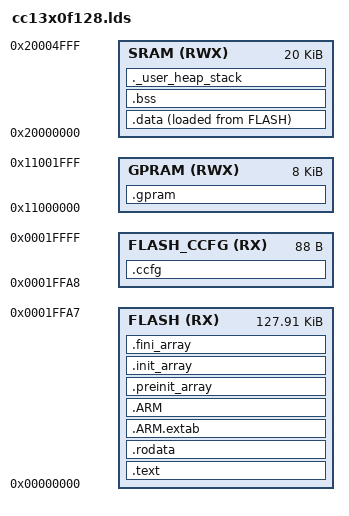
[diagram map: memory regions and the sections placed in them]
/*
 @file       cc13x0f128.lds
 @brief      CC13x0F128 linker configuration file for GNU compiler.

 @Revised     $Date: 2015-11-20 13:19:16 +0100 (fr, 20 nov 2015) $
 @Revision    $Revision: 16378 $

  Copyright (C) 2015 Texas Instruments Incorporated - http:www.ti.com/


  Redistribution and use in source and binary forms, with or without
  modification, are permitted provided that the following conditions
  are met:

    Redistributions of source code must retain the above copyright
    notice, this list of conditions and the following disclaimer.

    Redistributions in binary form must reproduce the above copyright
    notice, this list of conditions and the following disclaimer in the
    documentation and/or other materials provided with the distribution.

    Neither the name of Texas Instruments Incorporated nor the names of
    its contributors may be used to endorse or promote products derived
    from this software without specific prior written permission.

  THIS SOFTWARE IS PROVIDED BY THE COPYRIGHT HOLDERS AND CONTRIBUTORS
  "AS IS" AND ANY EXPRESS OR IMPLIED WARRANTIES, INCLUDING, BUT NOT
  LIMITED TO, THE IMPLIED WARRANTIES OF MERCHANTABILITY AND FITNESS FOR
  A PARTICULAR PURPOSE ARE DISCLAIMED. IN NO EVENT SHALL THE COPYRIGHT
  OWNER OR CONTRIBUTORS BE LIABLE FOR ANY DIRECT, INDIRECT, INCIDENTAL,
  SPECIAL, EXEMPLARY, OR CONSEQUENTIAL DAMAGES (INCLUDING, BUT NOT
  LIMITED TO, PROCUREMENT OF SUBSTITUTE GOODS OR SERVICES; LOSS OF USE,
  DATA, OR PROFITS; OR BUSINESS INTERRUPTION) HOWEVER CAUSED AND ON ANY
  THEORY OF LIABILITY, WHETHER IN CONTRACT, STRICT LIABILITY, OR TORT
  (INCLUDING NEGLIGENCE OR OTHERWISE) ARISING IN ANY WAY OUT OF THE USE
  OF THIS SOFTWARE, EVEN IF ADVISED OF THE POSSIBILITY OF SUCH DAMAGE.
*/

/* Entry Point */
ENTRY( ResetISR )

/* System memory map */
MEMORY
{
    /* Application stored in and executes from internal flash */
    /* Flash Size 128 KB */
    FLASH (RX) : ORIGIN = 0x0, LENGTH = 0x0001FFA8
    /* Customer Configuration Area (CCFG) */
    FLASH_CCFG (RX) : ORIGIN = 0x1FFA8, LENGTH = 88
    /* Application uses internal RAM for data */
    SRAM (RWX) : ORIGIN = 0x20000000, LENGTH = 0x5000
    /* Application can use GPRAM region as RAM if cache is disabled in the CCFG
       (DEFAULT_CCFG_SIZE_AND_DIS_FLAGS.SET_CCFG_SIZE_AND_DIS_FLAGS_DIS_GPRAM = 0) */
    GPRAM (RWX) : ORIGIN = 0x11000000, LENGTH = 0x2000
}

/*. Highest address of the stack. Used in startup file .*/
_estack = ORIGIN(SRAM) + LENGTH(SRAM); /*end of SRAM .*/

/*. Generate a link error if heap and stack donТt fit into RAM .*/
_Min_Heap_Size = 0;
_Min_Stack_Size = 0;


/* Section allocation in memory */
SECTIONS
{
    .text :
    {
        _text = .;
        KEEP(*(.vectors))
        *(.text*)
        *(.rodata*)
    KEEP (*(.init))
    KEEP (*(.fini))
        *(.eh_frame*)
        _etext = .;
    } > FLASH = 0
  /* Constant data into ROM memory*/
  .rodata :
  {
    . = ALIGN(4);
    *(.rodata)         /* .rodata sections (constants, strings, etc.) */
    *(.rodata*)        /* .rodata* sections (constants, strings, etc.) */
    . = ALIGN(4);
  } >FLASH

  .ARM.extab   : {
  	. = ALIGN(4);
  	*(.ARM.extab* .gnu.linkonce.armextab.*)
  	. = ALIGN(4);
  } >FLASH

  .ARM : {
    . = ALIGN(4);
    __exidx_start = .;
    *(.ARM.exidx*)
    __exidx_end = .;
    . = ALIGN(4);
  } >FLASH

  .preinit_array     :
  {
    . = ALIGN(4);
    PROVIDE_HIDDEN (__preinit_array_start = .);
    KEEP (*(.preinit_array*))
    PROVIDE_HIDDEN (__preinit_array_end = .);
    . = ALIGN(4);
  } >FLASH

  .init_array :
  {
    . = ALIGN(4);
    PROVIDE_HIDDEN (__init_array_start = .);
    KEEP (*(SORT(.init_array.*)))
    KEEP (*(.init_array*))
    PROVIDE_HIDDEN (__init_array_end = .);
    . = ALIGN(4);
  } >FLASH

  .fini_array :
  {
    . = ALIGN(4);
    PROVIDE_HIDDEN (__fini_array_start = .);
    KEEP (*(SORT(.fini_array.*)))
    KEEP (*(.fini_array*))
    PROVIDE_HIDDEN (__fini_array_end = .);
    . = ALIGN(4);
  } >FLASH

  /* Used by the startup to initialize data */
  _sidata = LOADADDR(.data);

  /* Initialized data sections into RAM memory */
  .data :
  {
    . = ALIGN(4);
    _data = .;        /* create a global symbol at data start */
    _sdata = .;        /* create a global symbol at data start */
    *(.data)           /* .data sections */
    *(.data*)          /* .data* sections */

    . = ALIGN(4);
    _edata = .;        /* define a global symbol at data end */
  } >SRAM AT> FLASH


  /* Uninitialized data section into RAM memory */
  . = ALIGN(4);
  .bss :
  {
    /* This is used by the startup in order to initialize the .bss secion */
    _bss = .;         /* define a global symbol at bss start */
    __bss_start__ = _bss;
    *(.bss)
    *(.bss*)
    *(COMMON)

    . = ALIGN(4);
    _ebss = .;         /* define a global symbol at bss end */
    __bss_end__ = _ebss;
  } >SRAM

    .ccfg :
    {
    } > FLASH_CCFG

  /* User_heap_stack section, used to check that there is enough RAM left */
  ._user_heap_stack :
  {
    . = ALIGN(8);
    PROVIDE ( end = . );
    PROVIDE ( _end = . );
    . = . + _Min_Heap_Size;
    . = . + _Min_Stack_Size;
    . = ALIGN(8);
  } >SRAM

    .gpram :
    {
    } > GPRAM
}
